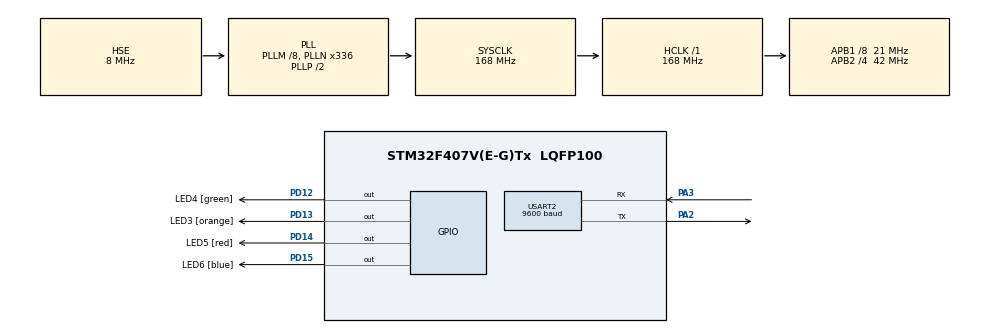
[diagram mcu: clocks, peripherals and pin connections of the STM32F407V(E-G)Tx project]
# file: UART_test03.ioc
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Mcu.Family=STM32F4
Mcu.Name=STM32F407V(E-G)Tx
Mcu.Package=LQFP100
NVIC.PriorityGroup=NVIC_PRIORITYGROUP_0
NVIC.USART2_IRQn=true\:0\:0\:false\:false\:true\:true
PA2.Mode=Asynchronous
PA2.Signal=USART2_TX
PA3.Mode=Asynchronous
PA3.Signal=USART2_RX
PD12.GPIO_Label=LED4 [green]
PD12.Signal=GPIO_Output
PD13.GPIO_Label=LED3 [orange]
PD13.Signal=GPIO_Output
PD14.GPIO_Label=LED5 [red]
PD14.Signal=GPIO_Output
PD15.GPIO_Label=LED6 [blue]
PD15.Signal=GPIO_Output
PH0-OSC_IN.Mode=HSE-External-Oscillator
PH0-OSC_IN.Signal=RCC_OSC_IN
PH1-OSC_OUT.Mode=HSE-External-Oscillator
PH1-OSC_OUT.Signal=RCC_OSC_OUT
ProjectManager.HeapSize=0x200
ProjectManager.StackSize=0x400
ProjectManager.TargetToolchain=Makefile
RCC.48MHZClocksFreq_Value=48000000
RCC.AHBFreq_Value=168000000
RCC.APB1CLKDivider=RCC_HCLK_DIV8
RCC.APB1Freq_Value=21000000
RCC.APB1TimFreq_Value=42000000
RCC.APB2CLKDivider=RCC_HCLK_DIV4
RCC.APB2Freq_Value=42000000
RCC.APB2TimFreq_Value=84000000
RCC.CortexFreq_Value=168000000
RCC.HCLKFreq_Value=168000000
RCC.HSE_VALUE=8000000
RCC.HSI_VALUE=16000000
RCC.LSE_VALUE=32768
RCC.PLLM=8
RCC.PLLN=336
RCC.PLLQ=7
RCC.PLLSourceVirtual=RCC_PLLSOURCE_HSE
RCC.SYSCLKFreq_VALUE=168000000
RCC.SYSCLKSource=RCC_SYSCLKSOURCE_PLLCLK
RCC.VCOOutputFreq_Value=336000000
USART2.BaudRate=9600
USART2.VirtualMode=VM_ASYNC
board=STM32F4DISCOVERY

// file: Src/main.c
/**
  ******************************************************************************
  * File Name          : main.c
  * Description        : Main program body
  ******************************************************************************
  * UART testing
  ******************************************************************************
  */

#include "main.h"
#include "stm32f4xx_hal.h"

GPIO_TypeDef* BUTTON_PORT[BUTTONn] = {KEY_BUTTON_GPIO_PORT};
const uint16_t BUTTON_PIN[BUTTONn] = {KEY_BUTTON_PIN};
const uint8_t BUTTON_IRQn[BUTTONn] = {KEY_BUTTON_EXTI_IRQn};

UART_HandleTypeDef huart2;
/* Buffer used for transmission */
uint8_t aTxBuffer[] = " ****UART_Tx_Test**** ";
/* USER CODE BEGIN PV */
/* Private variables ---------------------------------------------------------*/

/* USER CODE END PV */

void SystemClock_Config(void);
static void MX_GPIO_Init(void);
static void MX_USART2_UART_Init(void);

/* USER CODE BEGIN PFP */
/* Private function prototypes -----------------------------------------------*/

/* USER CODE END PFP */

int main(void)
{
  /* MCU Configuration----------------------------------------------------------*/
  /* Reset of all peripherals, Initializes the Flash interface and the Systick. */
  HAL_Init();
  /* Configure the system clock */
  SystemClock_Config();
  /* Initialize all configured peripherals */
  MX_GPIO_Init();
  /* Configure USER Button */
  BSP_PB_Init(BUTTON_KEY, BUTTON_MODE_GPIO);
  /* Configure UART */
  MX_USART2_UART_Init();

  /* Infinite loop */
  /* USER CODE BEGIN WHILE */
  /* Wait for USER Button press before starting the Communication */
  while (HAL_GPIO_ReadPin(BUTTON_PORT[BUTTON_KEY], BUTTON_PIN[BUTTON_KEY]) == GPIO_PIN_RESET)
  {
    HAL_GPIO_TogglePin(LED3_GPIO_Port, GPIO_PIN_13);
    HAL_Delay(40);
  }

  while(HAL_GPIO_ReadPin(BUTTON_PORT[BUTTON_KEY], BUTTON_PIN[BUTTON_KEY]) == GPIO_PIN_SET)
  {
  }

  while (1)
  {
    if(HAL_UART_Transmit_IT(&huart2, (uint8_t*)aTxBuffer, TXBUFFERSIZE)!= HAL_OK)
    {
      Error_Handler();
    }

  /* USER CODE END WHILE */

  }

}

/** System Clock Configuration
*/
void SystemClock_Config(void)
{

  RCC_OscInitTypeDef RCC_OscInitStruct;
  RCC_ClkInitTypeDef RCC_ClkInitStruct;

    /**Configure the main internal regulator output voltage
    */
  __HAL_RCC_PWR_CLK_ENABLE();

  __HAL_PWR_VOLTAGESCALING_CONFIG(PWR_REGULATOR_VOLTAGE_SCALE1);

    /**Initializes the CPU, AHB and APB busses clocks
    */
  RCC_OscInitStruct.OscillatorType = RCC_OSCILLATORTYPE_HSE;
  RCC_OscInitStruct.HSEState = RCC_HSE_ON;
  RCC_OscInitStruct.PLL.PLLState = RCC_PLL_ON;
  RCC_OscInitStruct.PLL.PLLSource = RCC_PLLSOURCE_HSE;
  RCC_OscInitStruct.PLL.PLLM = 8;
  RCC_OscInitStruct.PLL.PLLN = 336;
  RCC_OscInitStruct.PLL.PLLP = RCC_PLLP_DIV2;
  RCC_OscInitStruct.PLL.PLLQ = 7;
  if (HAL_RCC_OscConfig(&RCC_OscInitStruct) != HAL_OK)
  {
    _Error_Handler(__FILE__, __LINE__);
  }

    /**Initializes the CPU, AHB and APB busses clocks
    */
  RCC_ClkInitStruct.ClockType = RCC_CLOCKTYPE_HCLK|RCC_CLOCKTYPE_SYSCLK
                              |RCC_CLOCKTYPE_PCLK1|RCC_CLOCKTYPE_PCLK2;
  RCC_ClkInitStruct.SYSCLKSource = RCC_SYSCLKSOURCE_PLLCLK;
  RCC_ClkInitStruct.AHBCLKDivider = RCC_SYSCLK_DIV1;
  RCC_ClkInitStruct.APB1CLKDivider = RCC_HCLK_DIV8;
  RCC_ClkInitStruct.APB2CLKDivider = RCC_HCLK_DIV4;

  if (HAL_RCC_ClockConfig(&RCC_ClkInitStruct, FLASH_LATENCY_5) != HAL_OK)
  {
    _Error_Handler(__FILE__, __LINE__);
  }

    /**Configure the Systick interrupt time
    */
  HAL_SYSTICK_Config(HAL_RCC_GetHCLKFreq()/1000);

    /**Configure the Systick
    */
  HAL_SYSTICK_CLKSourceConfig(SYSTICK_CLKSOURCE_HCLK);

  /* SysTick_IRQn interrupt configuration */
  HAL_NVIC_SetPriority(SysTick_IRQn, 0, 0);
}

/* USART2 init function */
static void MX_USART2_UART_Init(void)
{

  huart2.Instance = USART2;
  huart2.Init.BaudRate = 9600;
  huart2.Init.WordLength = UART_WORDLENGTH_8B;
  huart2.Init.StopBits = UART_STOPBITS_1;
  huart2.Init.Parity = UART_PARITY_NONE;
  huart2.Init.Mode = UART_MODE_TX_RX;
  huart2.Init.HwFlowCtl = UART_HWCONTROL_NONE;
  huart2.Init.OverSampling = UART_OVERSAMPLING_16;
  if (HAL_UART_Init(&huart2) != HAL_OK)
  {
    _Error_Handler(__FILE__, __LINE__);
  }

}

/** Configure pins as
        * Analog
        * Input
        * Output
        * EVENT_OUT
        * EXTI
*/
static void MX_GPIO_Init(void)
{

  GPIO_InitTypeDef GPIO_InitStruct;

  /* GPIO Ports Clock Enable */
  __HAL_RCC_GPIOH_CLK_ENABLE();
  __HAL_RCC_GPIOA_CLK_ENABLE();
  __HAL_RCC_GPIOD_CLK_ENABLE();

  /*Configure GPIO pin Output Level */
  HAL_GPIO_WritePin(GPIOD, LED4_Pin|LED3_Pin|LED5_Pin|LED6_Pin, GPIO_PIN_RESET);

  /*Configure GPIO pins : LED4_Pin LED3_Pin LED5_Pin LED6_Pin */
  GPIO_InitStruct.Pin = LED4_Pin|LED3_Pin|LED5_Pin|LED6_Pin;
  GPIO_InitStruct.Mode = GPIO_MODE_OUTPUT_PP;
  GPIO_InitStruct.Pull = GPIO_NOPULL;
  GPIO_InitStruct.Speed = GPIO_SPEED_FREQ_LOW;
  HAL_GPIO_Init(GPIOD, &GPIO_InitStruct);

}

/**
  * @brief  Configures Button GPIO and EXTI Line.
  * @param  Button: Specifies the Button to be configured.
  *   This parameter should be: BUTTON_KEY
  * @param  Mode: Specifies Button mode.
  *   This parameter can be one of following parameters:
  *     @arg BUTTON_MODE_GPIO: Button will be used as simple IO
  *     @arg BUTTON_MODE_EXTI: Button will be connected to EXTI line with interrupt
  *                            generation capability
  */
void BSP_PB_Init(Button_TypeDef Button, ButtonMode_TypeDef Mode)
{
  GPIO_InitTypeDef GPIO_InitStruct;

  /* Enable the BUTTON Clock */
  BUTTONx_GPIO_CLK_ENABLE(Button);

  if (Mode == BUTTON_MODE_GPIO)
  {
    /* Configure Button pin as input */
    GPIO_InitStruct.Pin = BUTTON_PIN[Button];
    GPIO_InitStruct.Mode = GPIO_MODE_INPUT;
    GPIO_InitStruct.Pull = GPIO_NOPULL;
    GPIO_InitStruct.Speed = GPIO_SPEED_FAST;

    HAL_GPIO_Init(BUTTON_PORT[Button], &GPIO_InitStruct);
  }

  if (Mode == BUTTON_MODE_EXTI)
  {
    /* Configure Button pin as input with External interrupt */
    GPIO_InitStruct.Pin = BUTTON_PIN[Button];
    GPIO_InitStruct.Pull = GPIO_NOPULL;
    GPIO_InitStruct.Speed = GPIO_SPEED_FAST;
    GPIO_InitStruct.Mode = GPIO_MODE_IT_RISING;
    HAL_GPIO_Init(BUTTON_PORT[Button], &GPIO_InitStruct);

    /* Enable and set Button EXTI Interrupt to the lowest priority */
    HAL_NVIC_SetPriority((IRQn_Type)(BUTTON_IRQn[Button]), 0x0F, 0);
    HAL_NVIC_EnableIRQ((IRQn_Type)(BUTTON_IRQn[Button]));
  }
}
void _Error_Handler(char * file, int line)
{
  while(1)
  {
  }
}

/************************ (C) COPYRIGHT STMicroelectronics *****END OF FILE****/
